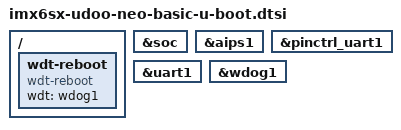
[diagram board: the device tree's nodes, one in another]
// SPDX-License-Identifier: GPL-2.0+

/ {
	wdt-reboot {
		compatible = "wdt-reboot";
		wdt = <&wdog1>;
		bootph-pre-ram;
	};
};

&soc {
	bootph-all;
};

&aips1 {
	bootph-all;
};

&pinctrl_uart1 {
	bootph-all;
};

&uart1 {
	bootph-all;
};

&wdog1 {
	bootph-pre-ram;
};
